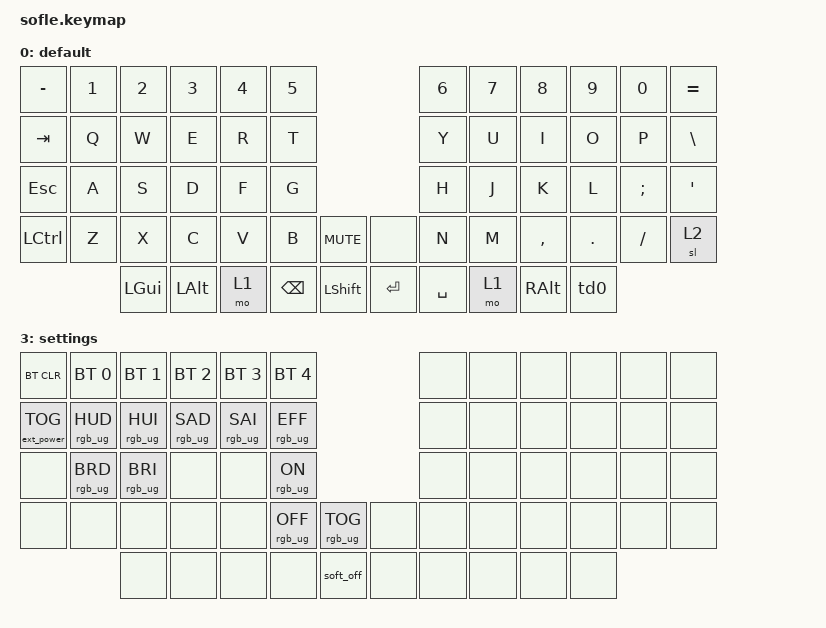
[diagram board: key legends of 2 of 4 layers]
/*
 * Copyright (c) 2020 The ZMK Contributors
 *
 * SPDX-License-Identifier: MIT
 */

#include <behaviors.dtsi>
#include <dt-bindings/zmk/bt.h>
#include <dt-bindings/zmk/ext_power.h>
#include <dt-bindings/zmk/keys.h>
#include <dt-bindings/zmk/pointing.h>
#include <dt-bindings/zmk/rgb.h>

#define ZMK_POINTING_DEFAULT_SCRL_VAL 300
#define BASE 0
#define LOWER 1
#define RAISE 2
#define ADJUST 3

// &pinctrl {
//     spi3_default: spi3_default {
//         group1 { psels = <NRF_PSEL(SPIM_MOSI, 0, 8)>; };
//     };
//     spi3_sleep: spi3_sleep {
//         group1 {
//             psels = <NRF_PSEL(SPIM_MOSI, 0, 8)>;
//             low-power-enable;
//         };
//     };
// };
// &spi3 {
//     compatible = "nordic,nrf-spim";
//     status = "okay";
//     pinctrl-0 = <&spi3_default>;
//     pinctrl-1 = <&spi3_sleep>;
//     pinctrl-names = "default", "sleep";
//     led_strip: ws2812@0 {
//         compatible = "worldsemi,ws2812-spi";
//         label = "WS2812";
//         /* SPI */
//         reg = <0>; /* ignored, but necessary for SPI bindings */
//         spi-max-frequency = <4000000>;
//         /* WS2812 */
//         chain-length = <30>;
//         spi-one-frame = <0x70>;
//         spi-zero-frame = <0x40>;
//         color-mapping = <LED_COLOR_ID_GREEN LED_COLOR_ID_RED LED_COLOR_ID_BLUE>;
//     };
// };
//  / {
//      chosen { zmk,underglow = &led_strip; };
//  };

&sl {
    release-after-ms = <3000>;
};

/ {
    behaviors {
        scroll_mouse: Mouse_Scroller {
            label = "Scroller As Mouse Wheel";
            compatible = "zmk,behavior-sensor-rotate";
            #sensor-binding-cells = <0>;
            bindings = <&msc SCRL_DOWN>, <&msc SCRL_UP>;

            tap-ms = <20>;
        };

        td0: tap_dance_0 {
            compatible = "zmk,behavior-tap-dance";
            #binding-cells = <0>;
            tapping-term-ms = <200>;
            bindings = <&kp LEFT_SHIFT>, <&kp CAPSLOCK>;
        };
    };

    conditional_layers { compatible = "zmk,conditional-layers"; };

    combos {
        compatible = "zmk,combos";

        activate_settings {
            bindings = <&mo 3>;
            key-positions = <57 58 59>;
        };

        to_layer1 {
            bindings = <&mo 1>;
            key-positions = <54 53>;
        };

        layer1 {
            bindings = <&mo 1>;
            key-positions = <55 56>;
        };
    };

    keymap {
        compatible = "zmk,keymap";

        default_layer {
            display-name = "default";
            bindings = <
&kp MINUS   &kp N1  &kp N2        &kp N3    &kp N4  &kp N5                                      &kp N6     &kp N7  &kp N8     &kp N9   &kp N0         &kp EQUAL
&kp TAB     &kp Q   &kp W         &kp E     &kp R   &kp T                                       &kp Y      &kp U   &kp I      &kp O    &kp P          &kp BACKSLASH
&kp ESCAPE  &kp A   &kp S         &kp D     &kp F   &kp G                                       &kp H      &kp J   &kp K      &kp L    &kp SEMICOLON  &kp SQT
&kp LCTRL   &kp Z   &kp X         &kp C     &kp V   &kp B          &kp C_MUTE        &none      &kp N      &kp M   &kp COMMA  &kp DOT  &kp FSLH       &sl 2
                    &kp LEFT_GUI  &kp LALT  &mo 1   &kp BACKSPACE  &kp LEFT_SHIFT    &kp ENTER  &kp SPACE  &mo 1   &kp RALT   &td0
            >;

            sensor-bindings = <&inc_dec_kp C_VOL_DN C_VOL_UP &scroll_mouse>;
        };

        second_layer {
            display-name = "second";
            bindings = <
&kp GRAVE  &kp F1  &kp F2  &kp F3  &kp F4  &kp F5                    &kp F6    &kp F7          &kp F8           &kp F9            &kp F10            &kp F11
&trans     &trans  &trans  &trans  &trans  &trans                    &trans    &kp LEFT_BRACE  &kp RIGHT_BRACE  &kp LEFT_BRACKET  &kp RIGHT_BRACKET  &kp F12
&trans     &trans  &trans  &trans  &trans  &trans                    &kp LEFT  &kp DOWN        &kp UP_ARROW     &kp RIGHT         &trans             &trans
&trans     &trans  &trans  &trans  &trans  &trans  &trans    &trans  &trans    &trans          &trans           &trans            &trans             &trans
                   &trans  &trans  &trans  &trans  &trans    &trans  &trans    &trans          &trans
            >;

            sensor-bindings = <&inc_dec_kp C_VOL_DN C_VOL_UP &scroll_mouse>;
        };

        accent_layer {
            display-name = "accent";
            bindings = <
&kp GRAVE  &kp F1     &kp F2  &kp F3     &kp F4  &kp F5                    &kp F6     &kp F7     &kp F8     &kp F9       &kp F10  &kp F11
&trans     &trans     &trans  &kp RA(G)  &trans  &trans                    &trans     &kp RA(J)  &kp RA(B)  &kp RA(DOT)  &trans   &kp F12
&trans     &kp RA(X)  &trans  &trans     &trans  &trans                    &trans     &trans     &trans     &trans       &trans   &trans
&trans     &trans     &trans  &trans     &trans  &trans  &trans    &trans  &kp RA(N)  &trans     &trans     &trans       &trans   &trans
                      &trans  &trans     &trans  &trans  &trans    &trans  &trans     &trans     &trans
            >;
        };

        settings_layer {
            display-name = "settings";
            bindings = <
&bt BT_CLR         &bt BT_SEL 0     &bt BT_SEL 1     &bt BT_SEL 2     &bt BT_SEL 3     &bt BT_SEL 4                               &none  &none  &none  &none  &none  &none
&ext_power EP_TOG  &rgb_ug RGB_HUD  &rgb_ug RGB_HUI  &rgb_ug RGB_SAD  &rgb_ug RGB_SAI  &rgb_ug RGB_EFF                            &none  &none  &none  &none  &none  &none
&none              &rgb_ug RGB_BRD  &rgb_ug RGB_BRI  &none            &none            &rgb_ug RGB_ON                             &none  &none  &none  &none  &none  &none
&none              &none            &none            &none            &none            &rgb_ug RGB_OFF  &rgb_ug RGB_TOG    &none  &none  &none  &none  &none  &none  &none
                                    &none            &none            &none            &none            &soft_off          &none  &none  &none  &none  &none
            >;
        };
    };
};
